# STM32F303ZET7 register map
File version: 1.0
STM32F303RDT6,STM32F303RDT7,STM32F303RET6,STM32F303RET7,STM32F303VDH6,STM32F303VDT6,STM32F303VEH6,STM32F303VEH7,STM32F303VET6,STM32F303VET7,STM32F303VEY6,STM32F303VEY7,STM32F303ZDT6,STM32F303ZDT7,STM32F303ZET6,STM32F303ZET7
Registers are 32-bit, access not given, reset 0x0 unless marked. A register's access mark holds for its fields unless they carry their own. Offsets are from the block's base; lines under a group give offsets from that group; [hi:lo] are bit positions; {n}, {i} and the like mark numbered series; 'fields as' and 'values as' point back to an identical list; <NAME> marks a mode.

## Memory map
0x1FFFF800 OB
0x40000000 TIM2
0x40000400 TIM3
0x40000800 TIM4
0x40001000 TIM6
0x40001400 TIM7
0x40002800 RTC
0x40002C00 WWDG
0x40003000 IWDG
0x40003400 I2S2ext
0x40003800 SPI2
0x40003C00 SPI3
0x40004000 I2S3ext
0x40004400 USART2
0x40004800 USART3
0x40004C00 UART4
0x40005000 UART5
0x40005400 I2C1
0x40005800 I2C2
0x40006400 CAN
0x40007000 PWR
0x40007400 DAC
0x40007400 DAC1
0x40007800 I2C3
0x40010000 SYSCFG
0x4001001C COMP1
0x4001001C COMP
0x40010020 COMP2
0x40010020 COMP12_COMMON
0x40010024 COMP3
0x40010028 COMP4
0x40010028 COMP34_COMMON
0x4001002C COMP5
0x40010030 COMP6
0x40010030 COMP56_COMMON
0x40010034 COMP7
0x40010038 OPAMP1
0x40010038 OPAMP
0x4001003C OPAMP2
0x40010040 OPAMP3
0x40010044 OPAMP4
0x40010400 EXTI
0x40012C00 TIM1
0x40013000 SPI1
0x40013400 TIM8
0x40013800 USART1
0x40013C00 SPI4
0x40014000 TIM15
0x40014400 TIM16
0x40014800 TIM17
0x40015000 TIM20
0x40020000 DMA1
0x40020400 DMA2
0x40021000 RCC
0x40022000 FLASH
0x40023000 CRC
0x40024000 TSC
0x48000000 GPIOA
0x48000400 GPIOB
0x48000800 GPIOC
0x48000C00 GPIOD
0x48001000 GPIOE
0x48001400 GPIOF
0x48001800 GPIOG
0x48001C00 GPIOH
0x50000000 ADC1
0x50000100 ADC2
0x50000300 ADC12_COMMON
0x50000400 ADC3
0x50000500 ADC4
0x50000700 ADC34_COMMON
0xE0042000 DBGMCU

## OB
Base 0x1FFFF800
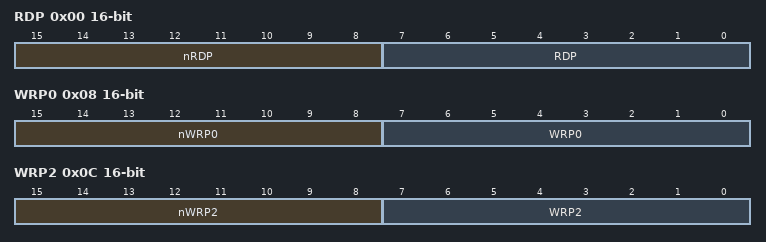
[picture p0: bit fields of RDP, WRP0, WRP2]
0x00 RDP 16-bit
  [15:8] nRDP, [7:0] RDP
0x02 USER 16-bit
  [31:24] nUSER, [23:16] USER
0x04 Data0 16-bit
0x06 Data1 16-bit
0x08 WRP0 16-bit
  [15:8] nWRP0, [7:0] WRP0
0x0A WRP1 16-bit
  [31:24] nWRP1, [23:16] WRP1
0x0C WRP2 16-bit
  [15:8] nWRP2, [7:0] WRP2
0x0E WRP3 16-bit
  [31:24] nWRP3, [23:16] WRP3

## TIM2
Base 0x40000000
Same registers: TIM3 0x40000400, TIM4 0x40000800, TIM6 0x40001000, TIM7 0x40001400, TIM1 0x40012C00, TIM8 0x40013400, TIM15 0x40014000, TIM16 0x40014400, TIM17 0x40014800, TIM20 0x40015000
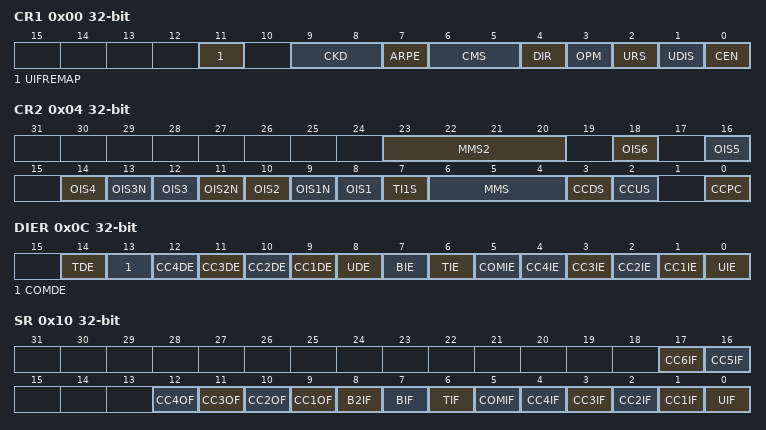
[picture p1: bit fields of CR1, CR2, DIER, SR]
0x00 CR1
  [11] UIFREMAP, [9:8] CKD, [7] ARPE, [6:5] CMS, [4] DIR, [3] OPM, [2] URS, [1] UDIS, [0] CEN
0x04 CR2
  [23:20] MMS2, [2n+6] OIS{n} (n=1..6), [13] OIS3N, [11] OIS2N, [9] OIS1N, [7] TI1S, [6:4] MMS, [3] CCDS, [2] CCUS, [0] CCPC
0x08 SMCR
  [15] ETP, [14] ECE, [13:12] ETPS, [11:8] ETF, [7] MSM, [6:4] TS, [3] OCCS, [16:0] SMS
0x0C DIER
  [14] TDE, [13] COMDE, [n+8] CC{n}DE (n=1..4), [8] UDE, [7] BIE, [6] TIE, [5] COMIE, [n] CC{n}IE (n=1..4), [0] UIE
0x10 SR
  [17] CC6IF, [16] CC5IF, [n+8] CC{n}OF (n=1..4), [8] B2IF, [7] BIF, [6] TIF, [5] COMIF, [n] CC{n}IF (n=1..4), [0] UIF
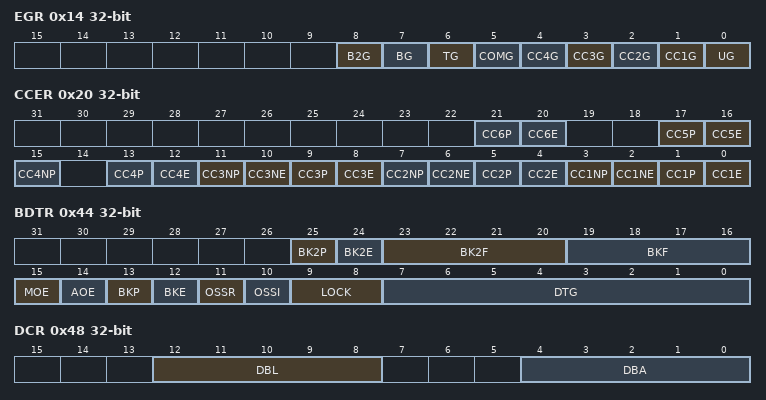
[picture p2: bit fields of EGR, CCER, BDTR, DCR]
0x14 EGR
  [8] B2G, [7] BG, [6] TG, [5] COMG, [n] CC{n}G (n=1..4), [0] UG
0x18 CCMR1
  [15] OC2CE, [24:12] OC2M, [11] OC2PE, [10] OC2FE, [9:8] CC2S, [7] OC1CE, [16:4] OC1M, [3] OC1PE, [2] OC1FE, [1:0] CC1S
0x1C CCMR2
  [15] OC4CE, [24:12] OC4M, [11] OC4PE, [10] OC4FE, [9:8] CC4S, [7] OC3CE, [16:4] OC3M, [3] OC3PE, [2] OC3FE, [1:0] CC3S
0x20 CCER
  [4n-3] CC{n}P (n=1..6), [4n-4] CC{n}E (n=1..6), [4n-1] CC{n}NP (n=1..4), [10] CC3NE, [6] CC2NE, [2] CC1NE
0x24 CNT
  [31] UIFCPY, [31:0] CNT
0x28 PSC
  [15:0] PSC
0x2C ARR
0x30 RCR
  [15:0] REP
{0x30+4i} CCR{i} (i=1..4)
  [15:0] CCR{i}
0x44 BDTR
  [25] BK2P, [24] BK2E, [23:20] BK2F, [19:16] BKF, [15] MOE, [14] AOE, [13] BKP, [12] BKE, [11] OSSR, [10] OSSI, [9:8] LOCK, [7:0] DTG
0x48 DCR
  [12:8] DBL, [4:0] DBA
0x4C DMAR
  [15:0] DMAB
0x50 OR
0x54 CCMR3
  [15] OC6CE, [24:12] OC6M, [11] OC6PE, [10] OC6FE, [7] OC5CE, [16:4] OC5M, [3] OC5PE, [2] OC5FE
0x58 CCR5
  [31] GC5C3, [30] GC5C2, [29] GC5C1, [31:0] CCR5
0x5C CCR6
  [15:0] CCR6
